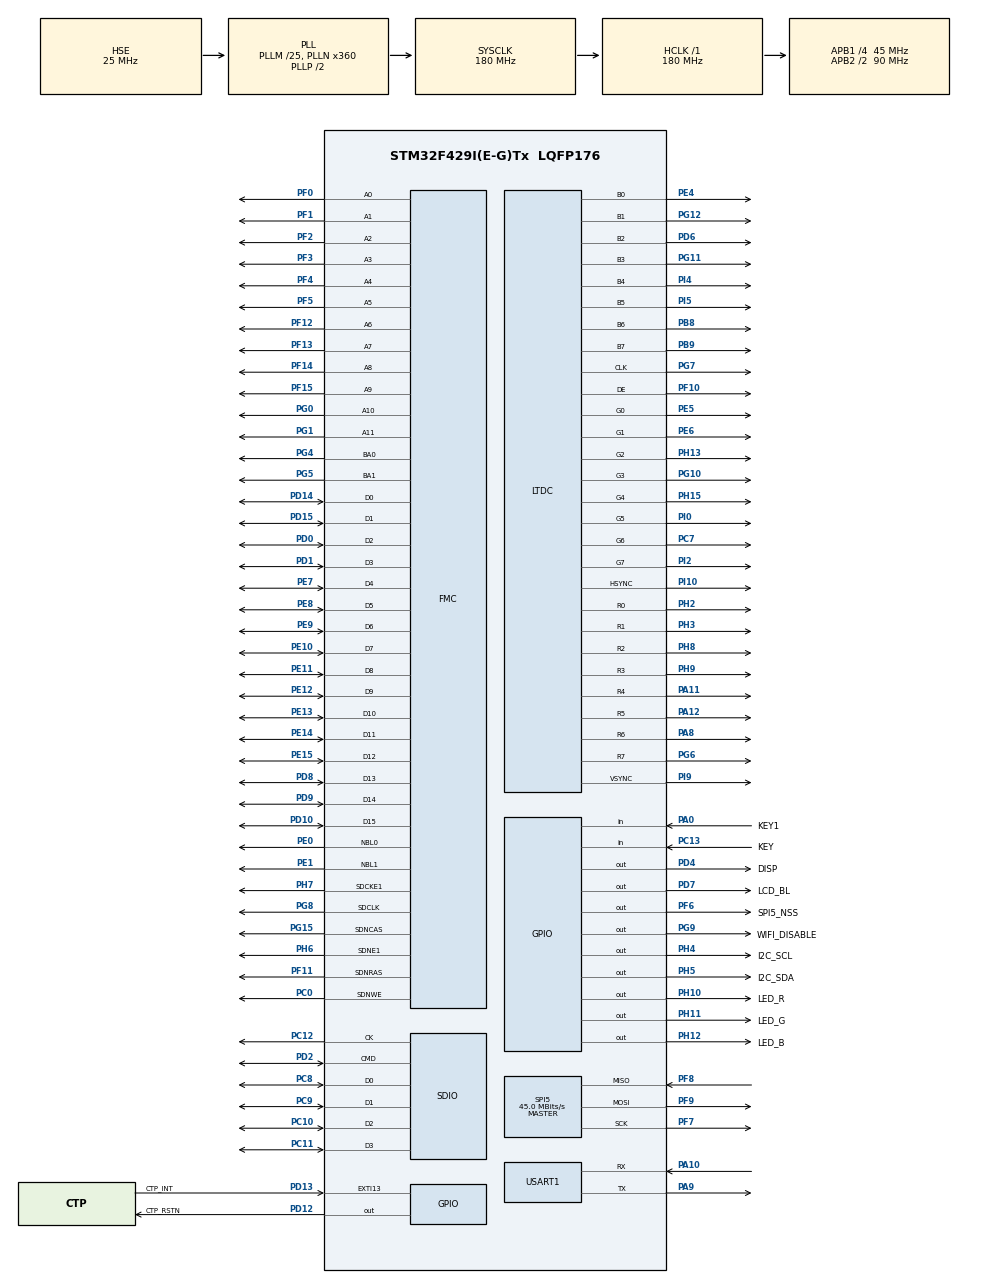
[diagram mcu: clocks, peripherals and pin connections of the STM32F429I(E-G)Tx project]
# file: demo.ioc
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DMA2D.ColorMode=DMA2D_OUTPUT_RGB888
DMA2D.Mode=DMA2D_R2M
DMA2D.OutputOffset=0xf
Dma.Request0=SDIO_TX
Dma.Request1=SDIO_RX
Dma.SDIO_RX.1.Direction=DMA_PERIPH_TO_MEMORY
Dma.SDIO_RX.1.FIFOMode=DMA_FIFOMODE_ENABLE
Dma.SDIO_RX.1.FIFOThreshold=DMA_FIFO_THRESHOLD_FULL
Dma.SDIO_RX.1.Instance=DMA2_Stream6
Dma.SDIO_RX.1.MemBurst=DMA_MBURST_INC4
Dma.SDIO_RX.1.MemDataAlignment=DMA_MDATAALIGN_WORD
Dma.SDIO_RX.1.MemInc=DMA_MINC_ENABLE
Dma.SDIO_RX.1.Mode=DMA_PFCTRL
Dma.SDIO_RX.1.PeriphBurst=DMA_PBURST_INC4
Dma.SDIO_RX.1.PeriphDataAlignment=DMA_PDATAALIGN_WORD
Dma.SDIO_RX.1.PeriphInc=DMA_PINC_DISABLE
Dma.SDIO_RX.1.Priority=DMA_PRIORITY_LOW
Dma.SDIO_TX.0.Direction=DMA_MEMORY_TO_PERIPH
Dma.SDIO_TX.0.FIFOMode=DMA_FIFOMODE_ENABLE
Dma.SDIO_TX.0.FIFOThreshold=DMA_FIFO_THRESHOLD_FULL
Dma.SDIO_TX.0.Instance=DMA2_Stream3
Dma.SDIO_TX.0.MemBurst=DMA_MBURST_INC4
Dma.SDIO_TX.0.MemDataAlignment=DMA_MDATAALIGN_WORD
Dma.SDIO_TX.0.MemInc=DMA_MINC_ENABLE
Dma.SDIO_TX.0.Mode=DMA_PFCTRL
Dma.SDIO_TX.0.PeriphBurst=DMA_PBURST_INC4
Dma.SDIO_TX.0.PeriphDataAlignment=DMA_PDATAALIGN_WORD
Dma.SDIO_TX.0.PeriphInc=DMA_PINC_DISABLE
Dma.SDIO_TX.0.Priority=DMA_PRIORITY_LOW
FATFS.BSP.number=1
FATFS._CODE_PAGE=936
FATFS._MAX_SS=4096
FATFS._USE_LFN=3
FATFS0.BSP.STBoard=false
FATFS0.BSP.api=Unknown
FATFS0.BSP.i2caddr=0
FATFS0.BSP.instance=PC13
FATFS0.BSP.ip=GPIO
FATFS0.BSP.mode=Input
FATFS0.BSP.name=Detect_SDIO
FATFS0.BSP.solution=PC13
FMC.CASLatency1=FMC_SDRAM_CAS_LATENCY_3
FMC.ExitSelfRefreshDelay1=7
FMC.LoadToActiveDelay1=2
FMC.RCDDelay1=2
FMC.RPDelay1=2
FMC.RPDelay2=2
FMC.ReadBurst1=FMC_SDRAM_RBURST_ENABLE
FMC.ReadBurst2=FMC_SDRAM_RBURST_ENABLE
FMC.ReadPipeDelay1=FMC_SDRAM_RPIPE_DELAY_1
FMC.ReadPipeDelay2=FMC_SDRAM_RPIPE_DELAY_1
FMC.RowCycleDelay1=7
FMC.RowCycleDelay2=7
FMC.SDClockPeriod1=FMC_SDRAM_CLOCK_PERIOD_2
FMC.SDClockPeriod2=FMC_SDRAM_CLOCK_PERIOD_2
FMC.SelfRefreshTime1=4
FMC.WriteRecoveryTime1=3
FREERTOS.INCLUDE_vTaskDelayUntil=1
FREERTOS.Queues01=gui_msg_q,8,uint32_t,0,Dynamic,NULL,NULL;hal_msg_q,16,uint32_t,0,Dynamic,NULL,NULL
FREERTOS.Tasks01=defaultTask,0,4096,StartDefaultTask,Default,NULL,Dynamic,NULL,NULL;LEDTask,-2,512,StartLEDTask,Default,NULL,Dynamic,NULL,NULL;GUITask,1,1024,StartTGUITask,Default,NULL,Dynamic,NULL,NULL
FREERTOS.configGENERATE_RUN_TIME_STATS=0
FREERTOS.configTOTAL_HEAP_SIZE=32768
FREERTOS.configUSE_IDLE_HOOK=1
FREERTOS.configUSE_MALLOC_FAILED_HOOK=1
FREERTOS.configUSE_STATS_FORMATTING_FUNCTIONS=1
FREERTOS.configUSE_TICK_HOOK=1
FREERTOS.configUSE_TRACE_FACILITY=1
GRAPHICS.BSP.number=4
GRAPHICS.Check_OTM8009A_PixelFormat-TouchGFX_F429_439=1
GRAPHICS.EA_3_command_line_template-TouchGFX_F429_439=\#EA_3_input_param1\#
GRAPHICS.EA_3_in_file1_param2=800
GRAPHICS.EA_3_in_file1_param3=480
GRAPHICS.EA_3_in_file1_param4=demo
GRAPHICS.EA_3_in_file1_param7=MDK-ARM V5
GRAPHICS.EA_3_os-TouchGFX_F429_439=Windows
GRAPHICS.EW_FRAME_BUFFER_COLOR_FORMAT-TouchGFX_F429_439=RGB888
GRAPHICS.GUI_NUM_LAYERS-TouchGFX_F429_439=1
GRAPHICS.TGFX_Pixel_Format_DPI_DSI-TouchGFX_F429_439=RGB888
GRAPHICS.TGFX_depth-TouchGFX_F429_439=24
GRAPHICS.USE_Embedded_Wizard-TouchGFX_F429_439=0
GRAPHICS.USE_STTouchGFX-TouchGFX_F429_439=1
GRAPHICS.Use_DSI-TouchGFX_F429_439=0
GRAPHICS.Use_SDRAM-TouchGFX_F429_439=SDRAM1_BANK2
GRAPHICS.Use_ili9341=0
GRAPHICS.Use_ili9341_Check-TouchGFX_F429_439=0
GRAPHICS0.BSP.STBoard=false
GRAPHICS0.BSP.api=Unknown
GRAPHICS0.BSP.i2caddr=0
GRAPHICS0.BSP.instance=PH10
GRAPHICS0.BSP.ip=GPIO
GRAPHICS0.BSP.mode=Output
GRAPHICS0.BSP.name=Chip Select
GRAPHICS0.BSP.solution=PH10
GRAPHICS1.BSP.STBoard=false
GRAPHICS1.BSP.api=Unknown
GRAPHICS1.BSP.i2caddr=0
GRAPHICS1.BSP.instance=PH11
GRAPHICS1.BSP.ip=GPIO
GRAPHICS1.BSP.mode=Output
GRAPHICS1.BSP.name=WRX High
GRAPHICS1.BSP.solution=PH11
GRAPHICS2.BSP.STBoard=false
GRAPHICS2.BSP.api=Unknown
GRAPHICS2.BSP.i2caddr=0
GRAPHICS2.BSP.instance=SPI5
GRAPHICS2.BSP.ip=SPI
GRAPHICS2.BSP.mode=Full-Duplex Master
GRAPHICS2.BSP.name=SPI_PIN
GRAPHICS2.BSP.solution=SPI5
GRAPHICS3.BSP.STBoard=false
GRAPHICS3.BSP.api=Unknown
GRAPHICS3.BSP.i2caddr=0
GRAPHICS3.BSP.instance=PH12
GRAPHICS3.BSP.ip=GPIO
GRAPHICS3.BSP.mode=Output
GRAPHICS3.BSP.name=RDX High
GRAPHICS3.BSP.solution=PH12
LTDC.ActiveW=800
LTDC.Alpha0_L0=255
LTDC.Alpha_L0=255
LTDC.BlendingFactor2_L0=LTDC_BLENDING_FACTOR2_CA
LTDC.Blue_L0=255
LTDC.FBStartAdress_L0=0xD0000000
LTDC.Green_L0=255
LTDC.HBP=46
LTDC.HFP=20
LTDC.HSync=1
LTDC.ImageHeight_L0=480
LTDC.ImageWidth_L0=800
LTDC.Layers=0
LTDC.PixelFormat_L0=LTDC_PIXEL_FORMAT_RGB888
LTDC.Red_L0=255
LTDC.VBP=23
LTDC.VFP=22
LTDC.VSync=1
LTDC.WindowX1_L0=800
LTDC.WindowY1_L0=480
Mcu.Family=STM32F4
Mcu.Name=STM32F429I(E-G)Tx
Mcu.Package=LQFP176
NVIC.DMA2D_IRQn=true\:5\:0\:false\:false\:true\:true\:true\:true
NVIC.DMA2_Stream3_IRQn=true\:5\:0\:false\:false\:true\:true\:false\:true
NVIC.DMA2_Stream6_IRQn=true\:5\:0\:false\:false\:true\:true\:false\:true
NVIC.LTDC_IRQn=true\:5\:0\:false\:false\:true\:true\:true\:true
NVIC.PriorityGroup=NVIC_PRIORITYGROUP_4
NVIC.SDIO_IRQn=true\:5\:0\:false\:false\:true\:true\:true\:true
NVIC.TIM6_DAC_IRQn=true\:0\:0\:false\:false\:true\:false\:false\:true
NVIC.TimeBase=TIM6_DAC_IRQn
NVIC.TimeBaseIP=TIM6
PA0/WKUP.GPIO_Label=KEY1
PA0/WKUP.GPIO_PuPd=GPIO_PULLDOWN
PA0/WKUP.Signal=GPIO_Input
PA10.Mode=Asynchronous
PA10.Signal=USART1_RX
PA11.Mode=RGB888
PA11.Signal=LTDC_R4
PA12.Mode=RGB888
PA12.Signal=LTDC_R5
PA13.Mode=Serial_Wire
PA13.Signal=SYS_JTMS-SWDIO
PA14.Mode=Serial_Wire
PA14.Signal=SYS_JTCK-SWCLK
PA8.Mode=RGB888
PA8.Signal=LTDC_R6
PA9.Mode=Asynchronous
PA9.Signal=USART1_TX
PB8.Mode=RGB888
PB8.Signal=LTDC_B6
PB9.Mode=RGB888
PB9.Signal=LTDC_B7
PC0.Signal=FMC_SDNWE
PC10.Mode=SD_4_bits_Wide_bus
PC10.Signal=SDIO_D2
PC11.Mode=SD_4_bits_Wide_bus
PC11.Signal=SDIO_D3
PC12.Mode=SD_4_bits_Wide_bus
PC12.Signal=SDIO_CK
PC13.GPIO_Label=KEY
PC13.GPIO_PuPd=GPIO_PULLDOWN
PC13.Signal=GPIO_Input
PC7.Mode=RGB888
PC7.Signal=LTDC_G6
PC8.Mode=SD_4_bits_Wide_bus
PC8.Signal=SDIO_D0
PC9.Mode=SD_4_bits_Wide_bus
PC9.Signal=SDIO_D1
PD0.Signal=FMC_D2_DA2
PD1.Signal=FMC_D3_DA3
PD10.Signal=FMC_D15_DA15
PD12.GPIO_Label=CTP_RSTN
PD12.GPIO_PuPd=GPIO_PULLDOWN
PD12.Signal=GPIO_Output
PD13.GPIO_Label=CTP_INT
PD13.GPIO_PuPd=GPIO_PULLDOWN
PD13.Signal=GPXTI13
PD14.Signal=FMC_D0_DA0
PD15.Signal=FMC_D1_DA1
PD2.Mode=SD_4_bits_Wide_bus
PD2.Signal=SDIO_CMD
PD4.GPIO_Label=DISP
PD4.GPIO_PuPd=GPIO_PULLUP
PD4.PinState=GPIO_PIN_SET
PD4.Signal=GPIO_Output
PD6.Mode=RGB888
PD6.Signal=LTDC_B2
PD7.GPIO_Label=LCD_BL
PD7.GPIO_PuPd=GPIO_PULLUP
PD7.PinState=GPIO_PIN_SET
PD7.Signal=GPIO_Output
PD8.Signal=FMC_D13_DA13
PD9.Signal=FMC_D14_DA14
PE0.Signal=FMC_NBL0
PE1.Signal=FMC_NBL1
PE10.Signal=FMC_D7_DA7
PE11.Signal=FMC_D8_DA8
PE12.Signal=FMC_D9_DA9
PE13.Signal=FMC_D10_DA10
PE14.Signal=FMC_D11_DA11
PE15.Signal=FMC_D12_DA12
PE4.Mode=RGB888
PE4.Signal=LTDC_B0
PE5.Mode=RGB888
PE5.Signal=LTDC_G0
PE6.Mode=RGB888
PE6.Signal=LTDC_G1
PE7.Signal=FMC_D4_DA4
PE8.Signal=FMC_D5_DA5
PE9.Signal=FMC_D6_DA6
PF0.Signal=FMC_A0
PF1.Signal=FMC_A1
PF10.Mode=RGB888
PF10.Signal=LTDC_DE
PF11.Signal=FMC_SDNRAS
PF12.Signal=FMC_A6
PF13.Signal=FMC_A7
PF14.Signal=FMC_A8
PF15.Signal=FMC_A9
PF2.Signal=FMC_A2
PF3.Signal=FMC_A3
PF4.Signal=FMC_A4
PF5.Signal=FMC_A5
PF6.GPIO_Label=SPI5_NSS
PF6.PinState=GPIO_PIN_SET
PF6.Signal=GPIO_Output
PF7.Mode=Full_Duplex_Master
PF7.Signal=SPI5_SCK
PF8.Mode=Full_Duplex_Master
PF8.Signal=SPI5_MISO
PF9.Mode=Full_Duplex_Master
PF9.Signal=SPI5_MOSI
PG0.Signal=FMC_A10
PG1.Signal=FMC_A11
PG10.Mode=RGB888
PG10.Signal=LTDC_G3
PG11.Mode=RGB888
PG11.Signal=LTDC_B3
PG12.Mode=RGB888
PG12.Signal=LTDC_B1
PG15.Signal=FMC_SDNCAS
PG4.Signal=FMC_A14_BA0
PG5.Signal=FMC_A15_BA1
PG6.Mode=RGB888
PG6.Signal=LTDC_R7
PG7.Mode=RGB888
PG7.Signal=LTDC_CLK
PG8.Signal=FMC_SDCLK
PG9.GPIO_Label=WIFI_DISABLE
PG9.GPIO_PuPd=GPIO_PULLDOWN
PG9.Signal=GPIO_Output
PH0/OSC_IN.Mode=HSE-External-Oscillator
PH0/OSC_IN.Signal=RCC_OSC_IN
PH1/OSC_OUT.Mode=HSE-External-Oscillator
PH1/OSC_OUT.Signal=RCC_OSC_OUT
PH10.GPIO_Label=LED_R
PH10.GPIO_PuPd=GPIO_PULLUP
PH10.GPIO_Speed=GPIO_SPEED_FREQ_HIGH
PH10.PinState=GPIO_PIN_SET
PH10.Signal=GPIO_Output
PH11.GPIO_Label=LED_G
PH11.GPIO_PuPd=GPIO_PULLUP
PH11.GPIO_Speed=GPIO_SPEED_FREQ_HIGH
PH11.PinState=GPIO_PIN_SET
PH11.Signal=GPIO_Output
PH12.GPIO_Label=LED_B
PH12.GPIO_PuPd=GPIO_PULLUP
PH12.GPIO_Speed=GPIO_SPEED_FREQ_HIGH
PH12.PinState=GPIO_PIN_SET
PH12.Signal=GPIO_Output
PH13.Mode=RGB888
PH13.Signal=LTDC_G2
PH15.Mode=RGB888
PH15.Signal=LTDC_G4
PH2.Mode=RGB888
PH2.Signal=LTDC_R0
PH3.Mode=RGB888
PH3.Signal=LTDC_R1
PH4.GPIO_Label=I2C_SCL
PH4.Signal=GPIO_Output
PH5.GPIO_Label=I2C_SDA
PH5.Signal=GPIO_Output
PH6.Mode=SdramChipSelect2_1
PH6.Signal=FMC_SDNE1
PH7.Mode=SdramChipSelect2_1
PH7.Signal=FMC_SDCKE1
PH8.Mode=RGB888
PH8.Signal=LTDC_R2
PH9.Mode=RGB888
PH9.Signal=LTDC_R3
PI0.Mode=RGB888
PI0.Signal=LTDC_G5
PI10.Mode=RGB888
PI10.Signal=LTDC_HSYNC
PI2.Mode=RGB888
PI2.Signal=LTDC_G7
PI4.Mode=RGB888
PI4.Signal=LTDC_B4
PI5.Mode=RGB888
PI5.Signal=LTDC_B5
PI9.Mode=RGB888
PI9.Signal=LTDC_VSYNC
ProjectManager.HeapSize=0x400
ProjectManager.StackSize=0x400
ProjectManager.TargetToolchain=MDK-ARM V5
RCC.48MHZClocksFreq_Value=45000000
RCC.AHBFreq_Value=180000000
RCC.APB1CLKDivider=RCC_HCLK_DIV4
RCC.APB1Freq_Value=45000000
RCC.APB1TimFreq_Value=90000000
RCC.APB2CLKDivider=RCC_HCLK_DIV2
RCC.APB2Freq_Value=90000000
RCC.APB2TimFreq_Value=180000000
RCC.CortexFreq_Value=180000000
RCC.HCLKFreq_Value=180000000
RCC.HSE_VALUE=25000000
RCC.HSI_VALUE=16000000
RCC.LSE_VALUE=32768
RCC.PLLM=25
RCC.PLLN=360
RCC.PLLQ=8
RCC.PLLSAIDivR=RCC_PLLSAIDIVR_8
RCC.PLLSAIN=420
RCC.PLLSAIR=5
RCC.PLLSourceVirtual=RCC_PLLSOURCE_HSE
RCC.SYSCLKFreq_VALUE=180000000
RCC.SYSCLKSource=RCC_SYSCLKSOURCE_PLLCLK
RCC.VCOOutputFreq_Value=360000000
SH.FMC_A0.0=FMC_A0,12b-sda1
SH.FMC_A1.0=FMC_A1,12b-sda1
SH.FMC_A10.0=FMC_A10,12b-sda1
SH.FMC_A11.0=FMC_A11,12b-sda1
SH.FMC_A14_BA0.0=FMC_BA0,FourSdramBanks1
SH.FMC_A15_BA1.0=FMC_BA1,FourSdramBanks1
SH.FMC_A2.0=FMC_A2,12b-sda1
SH.FMC_A3.0=FMC_A3,12b-sda1
SH.FMC_A4.0=FMC_A4,12b-sda1
SH.FMC_A5.0=FMC_A5,12b-sda1
SH.FMC_A6.0=FMC_A6,12b-sda1
SH.FMC_A7.0=FMC_A7,12b-sda1
SH.FMC_A8.0=FMC_A8,12b-sda1
SH.FMC_A9.0=FMC_A9,12b-sda1
SH.FMC_D0_DA0.0=FMC_D0,sd-16b-d1
SH.FMC_D10_DA10.0=FMC_D10,sd-16b-d1
SH.FMC_D11_DA11.0=FMC_D11,sd-16b-d1
SH.FMC_D12_DA12.0=FMC_D12,sd-16b-d1
SH.FMC_D13_DA13.0=FMC_D13,sd-16b-d1
SH.FMC_D14_DA14.0=FMC_D14,sd-16b-d1
SH.FMC_D15_DA15.0=FMC_D15,sd-16b-d1
SH.FMC_D1_DA1.0=FMC_D1,sd-16b-d1
SH.FMC_D2_DA2.0=FMC_D2,sd-16b-d1
SH.FMC_D3_DA3.0=FMC_D3,sd-16b-d1
SH.FMC_D4_DA4.0=FMC_D4,sd-16b-d1
SH.FMC_D5_DA5.0=FMC_D5,sd-16b-d1
SH.FMC_D6_DA6.0=FMC_D6,sd-16b-d1
SH.FMC_D7_DA7.0=FMC_D7,sd-16b-d1
SH.FMC_D8_DA8.0=FMC_D8,sd-16b-d1
SH.FMC_D9_DA9.0=FMC_D9,sd-16b-d1
SH.FMC_NBL0.0=FMC_NBL0,Sd2ByteEnable1
SH.FMC_NBL1.0=FMC_NBL1,Sd2ByteEnable1
SH.FMC_SDCLK.0=FMC_SDCLK,12b-sda1
SH.FMC_SDNCAS.0=FMC_SDNCAS,12b-sda1
SH.FMC_SDNRAS.0=FMC_SDNRAS,12b-sda1
SH.FMC_SDNWE.0=FMC_SDNWE,12b-sda1
SPI5.CLKPhase=SPI_PHASE_2EDGE
SPI5.CLKPolarity=SPI_POLARITY_HIGH
SPI5.CalculateBaudRate=45.0 MBits/s
SPI5.Direction=SPI_DIRECTION_2LINES
SPI5.Mode=SPI_MODE_MASTER
SPI5.VirtualType=VM_MASTER
USART1.VirtualMode=VM_ASYNC
VP_CRC_VS_CRC.Mode=CRC_Activate
VP_DMA2D_VS_DMA2D.Mode=DMA2D_Activate
VP_FATFS_VS_SDIO.Mode=SDIO
VP_FREERTOS_VS_CMSIS_V1.Mode=CMSIS_V1
VP_GRAPHICS_VS-DisplayInterface-LTDC.Mode=Display Parallel Interface using LTDC
VP_GRAPHICS_VS-Touch-GFX.Mode=TouchGFX_F429_439
VP_SYS_VS_tim6.Mode=TIM6
VP_TIM7_VS_ClockSourceINT.Mode=Enable_Timer
board=custom

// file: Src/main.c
/* USER CODE BEGIN Header */
/**
  ******************************************************************************
  * @file           : main.c
  * @brief          : Main program body
  ******************************************************************************
  * @attention
  *
  * <h2><center>&copy; Copyright (c) 2019 STMicroelectronics.
  * All rights reserved.</center></h2>
  *
  * This software component is licensed by ST under Ultimate Liberty license
  * SLA0044, the "License"; You may not use this file except in compliance with
  * the License. You may obtain a copy of the License at:
  *                             www.st.com/SLA0044
  *
  ******************************************************************************
  */
/* USER CODE END Header */

#include "main.h"
#include "cmsis_os.h"
#include "crc.h"
#include "dma.h"
#include "fatfs.h"
#include "sdio.h"
#include "spi.h"
#include "tim.h"
#include "usart.h"
#include "gpio.h"

/* USER CODE BEGIN Includes */
#include "gt9xx.h"
/* USER CODE END Includes */

void SystemClock_Config(void);
void MX_FREERTOS_Init(void);
extern void GRAPHICS_HW_Init(void);
extern void GRAPHICS_Init(void);
extern void GRAPHICS_MainTask(void);

int main(void)
{

  /* MCU Configuration--------------------------------------------------------*/

  /* Reset of all peripherals, Initializes the Flash interface and the Systick. */
  HAL_Init();

  /* Configure the system clock */
  SystemClock_Config();

  /* Initialize all configured peripherals */
  MX_GPIO_Init();
  MX_DMA_Init();
  MX_CRC_Init();
  MX_USART1_UART_Init();
  MX_SDIO_SD_Init();
  MX_TIM7_Init();
  /* USER CODE BEGIN 2 */
	MX_SPI5_Init();
	__HAL_SPI_ENABLE(&hspi5);                    //使能SPI5
	GTP_Init_Panel();
  /* USER CODE END 2 */

/* Initialise the graphical hardware */
  GRAPHICS_HW_Init();

  /* Initialise the graphical stack engine */
  GRAPHICS_Init();

  /* Call init function for freertos objects (in freertos.c) */
  MX_FREERTOS_Init();

  /* Start scheduler */
  osKernelStart();

  /* We should never get here as control is now taken by the scheduler */

  /* Infinite loop */
  while (1)
  {

  }
}

void SystemClock_Config(void)
{
  RCC_OscInitTypeDef RCC_OscInitStruct = {0};
  RCC_ClkInitTypeDef RCC_ClkInitStruct = {0};
  RCC_PeriphCLKInitTypeDef PeriphClkInitStruct = {0};

  /** Configure the main internal regulator output voltage
  */
  __HAL_RCC_PWR_CLK_ENABLE();
  __HAL_PWR_VOLTAGESCALING_CONFIG(PWR_REGULATOR_VOLTAGE_SCALE1);
  /** Initializes the CPU, AHB and APB busses clocks
  */
  RCC_OscInitStruct.OscillatorType = RCC_OSCILLATORTYPE_HSE;
  RCC_OscInitStruct.HSEState = RCC_HSE_ON;
  RCC_OscInitStruct.PLL.PLLState = RCC_PLL_ON;
  RCC_OscInitStruct.PLL.PLLSource = RCC_PLLSOURCE_HSE;
  RCC_OscInitStruct.PLL.PLLM = 25;
  RCC_OscInitStruct.PLL.PLLN = 360;
  RCC_OscInitStruct.PLL.PLLP = RCC_PLLP_DIV2;
  RCC_OscInitStruct.PLL.PLLQ = 8;
  if (HAL_RCC_OscConfig(&RCC_OscInitStruct) != HAL_OK)
  {
    Error_Handler();
  }
  /** Activate the Over-Drive mode
  */
  if (HAL_PWREx_EnableOverDrive() != HAL_OK)
  {
    Error_Handler();
  }
  /** Initializes the CPU, AHB and APB busses clocks
  */
  RCC_ClkInitStruct.ClockType = RCC_CLOCKTYPE_HCLK|RCC_CLOCKTYPE_SYSCLK
                              |RCC_CLOCKTYPE_PCLK1|RCC_CLOCKTYPE_PCLK2;
  RCC_ClkInitStruct.SYSCLKSource = RCC_SYSCLKSOURCE_PLLCLK;
  RCC_ClkInitStruct.AHBCLKDivider = RCC_SYSCLK_DIV1;
  RCC_ClkInitStruct.APB1CLKDivider = RCC_HCLK_DIV4;
  RCC_ClkInitStruct.APB2CLKDivider = RCC_HCLK_DIV2;

  if (HAL_RCC_ClockConfig(&RCC_ClkInitStruct, FLASH_LATENCY_5) != HAL_OK)
  {
    Error_Handler();
  }
  PeriphClkInitStruct.PeriphClockSelection = RCC_PERIPHCLK_LTDC;
  PeriphClkInitStruct.PLLSAI.PLLSAIN = 420;
  PeriphClkInitStruct.PLLSAI.PLLSAIR = 7;
  PeriphClkInitStruct.PLLSAIDivR = RCC_PLLSAIDIVR_4;
  if (HAL_RCCEx_PeriphCLKConfig(&PeriphClkInitStruct) != HAL_OK)
  {
    Error_Handler();
  }
}

void HAL_TIM_PeriodElapsedCallback(TIM_HandleTypeDef *htim)
{
  if (htim->Instance == TIM6) {
    HAL_IncTick();
  }
}

void Error_Handler(void)
{
}

/************************ (C) COPYRIGHT STMicroelectronics *****END OF FILE****/

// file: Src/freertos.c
/* USER CODE BEGIN Header */
/**
  ******************************************************************************
  * File Name          : freertos.c
  * Description        : Code for freertos applications
  ******************************************************************************
  * @attention
  *
  * <h2><center>&copy; Copyright (c) 2019 STMicroelectronics.
  * All rights reserved.</center></h2>
  *
  * This software component is licensed by ST under Ultimate Liberty license
  * SLA0044, the "License"; You may not use this file except in compliance with
  * the License. You may obtain a copy of the License at:
  *                             www.st.com/SLA0044
  *
  ******************************************************************************
  */
/* USER CODE END Header */

#include "FreeRTOS.h"
#include "task.h"
#include "main.h"

/* USER CODE BEGIN PTD */
extern volatile uint32_t CPU_RunTime;
/* USER CODE END PTD */

/* USER CODE BEGIN FunctionPrototypes */
extern void GRAPHICS_MainTask(void);
/* USER CODE END FunctionPrototypes */

/* GetIdleTaskMemory prototype (linked to static allocation support) */
void vApplicationGetIdleTaskMemory( StaticTask_t **ppxIdleTaskTCBBuffer, StackType_t **ppxIdleTaskStackBuffer, uint32_t *pulIdleTaskStackSize );

/* Hook prototypes */
void vApplicationIdleHook(void);
void vApplicationTickHook(void);
void vApplicationMallocFailedHook(void);

/* USER CODE BEGIN 2 */
__weak void vApplicationIdleHook( void )
{
   /* vApplicationIdleHook() will only be called if configUSE_IDLE_HOOK is set
   to 1 in FreeRTOSConfig.h. It will be called on each iteration of the idle
   task. It is essential that code added to this hook function never attempts
   to block in any way (for example, call xQueueReceive() with a block time
   specified, or call vTaskDelay()). If the application makes use of the
   vTaskDelete() API function (as this demo application does) then it is also
   important that vApplicationIdleHook() is permitted to return to its calling
   function, because it is the responsibility of the idle task to clean up
   memory allocated by the kernel to any task that has since been deleted. */
}
/* USER CODE END 2 */

/* USER CODE BEGIN 3 */
__weak void vApplicationTickHook( void )
{
   /* This function will be called by each tick interrupt if
   configUSE_TICK_HOOK is set to 1 in FreeRTOSConfig.h. User code can be
   added here, but the tick hook is called from an interrupt context, so
   code must not attempt to block, and only the interrupt safe FreeRTOS API
   functions can be used (those that end in FromISR()). */
}
/* USER CODE END 3 */

/* USER CODE BEGIN 5 */
__weak void vApplicationMallocFailedHook(void)
{
   /* vApplicationMallocFailedHook() will only be called if
   configUSE_MALLOC_FAILED_HOOK is set to 1 in FreeRTOSConfig.h. It is a hook
   function that will get called if a call to pvPortMalloc() fails.
   pvPortMalloc() is called internally by the kernel whenever a task, queue,
   timer or semaphore is created. It is also called by various parts of the
   demo application. If heap_1.c or heap_2.c are used, then the size of the
   heap available to pvPortMalloc() is defined by configTOTAL_HEAP_SIZE in
   FreeRTOSConfig.h, and the xPortGetFreeHeapSize() API function can be used
   to query the size of free heap space that remains (although it does not
   provide information on how the remaining heap might be fragmented). */
}
/* USER CODE END 5 */

/* USER CODE BEGIN GET_IDLE_TASK_MEMORY */
static StaticTask_t xIdleTaskTCBBuffer;
static StackType_t xIdleStack[configMINIMAL_STACK_SIZE];

void vApplicationGetIdleTaskMemory( StaticTask_t **ppxIdleTaskTCBBuffer, StackType_t **ppxIdleTaskStackBuffer, uint32_t *pulIdleTaskStackSize )
{
  *ppxIdleTaskTCBBuffer = &xIdleTaskTCBBuffer;
  *ppxIdleTaskStackBuffer = &xIdleStack[0];
  *pulIdleTaskStackSize = configMINIMAL_STACK_SIZE;
  /* place for user code */
}
/* USER CODE END GET_IDLE_TASK_MEMORY */

/************************ (C) COPYRIGHT STMicroelectronics *****END OF FILE****/
